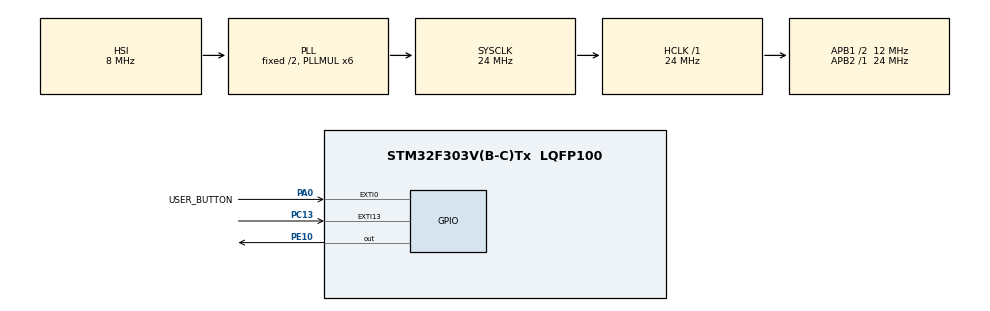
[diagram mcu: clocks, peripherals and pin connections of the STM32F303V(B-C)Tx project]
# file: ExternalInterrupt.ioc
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Mcu.Family=STM32F3
Mcu.Name=STM32F303V(B-C)Tx
Mcu.Package=LQFP100
NVIC.EXTI15_10_IRQn=true\:0\:1\:true\:false\:true\:true\:true\:true
NVIC.PriorityGroup=NVIC_PRIORITYGROUP_0
PA0.GPIO_Label=USER_BUTTON
PA0.Signal=GPXTI0
PC13.GPIO_ModeDefaultEXTI=GPIO_MODE_IT_FALLING
PC13.Signal=GPXTI13
PE10.Signal=GPIO_Output
ProjectManager.HeapSize=0x200
ProjectManager.StackSize=0x400
ProjectManager.TargetToolchain=STM32CubeIDE
RCC.AHBFreq_Value=24000000
RCC.APB1CLKDivider=RCC_HCLK_DIV2
RCC.APB1Freq_Value=12000000
RCC.APB1TimFreq_Value=24000000
RCC.APB2Freq_Value=24000000
RCC.APB2TimFreq_Value=24000000
RCC.CortexFreq_Value=24000000
RCC.HCLKFreq_Value=24000000
RCC.HSE_VALUE=8000000
RCC.HSI_VALUE=8000000
RCC.LSE_VALUE=32768
RCC.PLLMUL=RCC_PLL_MUL6
RCC.SYSCLKFreq_VALUE=24000000
RCC.SYSCLKSourceVirtual=RCC_SYSCLKSOURCE_PLLCLK
RCC.USBFreq_Value=24000000
board=STM32F3DISCOVERY

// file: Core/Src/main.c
/* USER CODE BEGIN Header */
/**
  ******************************************************************************
  * @file           : main.c
  * @brief          : Main program body
  ******************************************************************************
  * @attention
  *
  * Copyright (c) 2023 STMicroelectronics.
  * All rights reserved.
  *
  * This software is licensed under terms that can be found in the LICENSE file
  * in the root directory of this software component.
  * If no LICENSE file comes with this software, it is provided AS-IS.
  *
  ******************************************************************************
  */
/* USER CODE END Header */
#include "main.h"

void SystemClock_Config(void);
static void MX_GPIO_Init(void);
/* USER CODE BEGIN PFP */
uint8_t modeSelection =0;
/* USER CODE END PFP */

/* USER CODE BEGIN 0 */
void HAL_GPIO_EXTI_Callback(uint16_t GPIO_Pin)
{
  /* Prevent unused argument(s) compilation warning */
  UNUSED(GPIO_Pin);
  if(GPIO_Pin == USER_BUTTON_PIN_Pin){
	  modeSelection++;
	  if(modeSelection > 2){
		  modeSelection=0;
	  }
  }

}

/* USER CODE END 0 */

int main(void)
{

  /* MCU Configuration--------------------------------------------------------*/

  /* Reset of all peripherals, Initializes the Flash interface and the Systick. */
  HAL_Init();

  /* Configure the system clock */
  SystemClock_Config();

  /* Initialize all configured peripherals */
  MX_GPIO_Init();

  /* Infinite loop */
  while (1)
  {
	  if(modeSelection==0){
		  HAL_GPIO_TogglePin(GPIOE, GPIO_PIN_10);
		  HAL_Delay(200);
	  }
	  else if(modeSelection==1){
		  HAL_GPIO_WritePin(GPIOE, GPIO_PIN_10, GPIO_PIN_RESET);
		  HAL_Delay(200);
	  }
	  else if(modeSelection==2){
		  HAL_GPIO_WritePin(GPIOE, GPIO_PIN_10, GPIO_PIN_SET);
		  HAL_Delay(200);
	  }

  }
}

void SystemClock_Config(void)
{
  RCC_OscInitTypeDef RCC_OscInitStruct = {0};
  RCC_ClkInitTypeDef RCC_ClkInitStruct = {0};

  /** Initializes the RCC Oscillators according to the specified parameters
  * in the RCC_OscInitTypeDef structure.
  */
  RCC_OscInitStruct.OscillatorType = RCC_OSCILLATORTYPE_HSI;
  RCC_OscInitStruct.HSIState = RCC_HSI_ON;
  RCC_OscInitStruct.HSICalibrationValue = RCC_HSICALIBRATION_DEFAULT;
  RCC_OscInitStruct.PLL.PLLState = RCC_PLL_ON;
  RCC_OscInitStruct.PLL.PLLSource = RCC_PLLSOURCE_HSI;
  RCC_OscInitStruct.PLL.PLLMUL = RCC_PLL_MUL6;
  if (HAL_RCC_OscConfig(&RCC_OscInitStruct) != HAL_OK)
  {
    Error_Handler();
  }

  /** Initializes the CPU, AHB and APB buses clocks
  */
  RCC_ClkInitStruct.ClockType = RCC_CLOCKTYPE_HCLK|RCC_CLOCKTYPE_SYSCLK
                              |RCC_CLOCKTYPE_PCLK1|RCC_CLOCKTYPE_PCLK2;
  RCC_ClkInitStruct.SYSCLKSource = RCC_SYSCLKSOURCE_PLLCLK;
  RCC_ClkInitStruct.AHBCLKDivider = RCC_SYSCLK_DIV1;
  RCC_ClkInitStruct.APB1CLKDivider = RCC_HCLK_DIV2;
  RCC_ClkInitStruct.APB2CLKDivider = RCC_HCLK_DIV1;

  if (HAL_RCC_ClockConfig(&RCC_ClkInitStruct, FLASH_LATENCY_0) != HAL_OK)
  {
    Error_Handler();
  }
}

static void MX_GPIO_Init(void)
{
  GPIO_InitTypeDef GPIO_InitStruct = {0};

  /* GPIO Ports Clock Enable */
  __HAL_RCC_GPIOC_CLK_ENABLE();
  __HAL_RCC_GPIOA_CLK_ENABLE();
  __HAL_RCC_GPIOE_CLK_ENABLE();

  /*Configure GPIO pin Output Level */
  HAL_GPIO_WritePin(GPIOE, GPIO_PIN_10, GPIO_PIN_RESET);

  /*Configure GPIO pin : PC13 */
  GPIO_InitStruct.Pin = GPIO_PIN_13;
  GPIO_InitStruct.Mode = GPIO_MODE_IT_FALLING;
  GPIO_InitStruct.Pull = GPIO_NOPULL;
  HAL_GPIO_Init(GPIOC, &GPIO_InitStruct);

  /*Configure GPIO pin : USER_BUTTON_PIN_Pin */
  GPIO_InitStruct.Pin = USER_BUTTON_PIN_Pin;
  GPIO_InitStruct.Mode = GPIO_MODE_IT_RISING;
  GPIO_InitStruct.Pull = GPIO_NOPULL;
  HAL_GPIO_Init(USER_BUTTON_PIN_GPIO_Port, &GPIO_InitStruct);

  /*Configure GPIO pin : PE10 */
  GPIO_InitStruct.Pin = GPIO_PIN_10;
  GPIO_InitStruct.Mode = GPIO_MODE_OUTPUT_PP;
  GPIO_InitStruct.Pull = GPIO_NOPULL;
  GPIO_InitStruct.Speed = GPIO_SPEED_FREQ_LOW;
  HAL_GPIO_Init(GPIOE, &GPIO_InitStruct);

  /* EXTI interrupt init*/
  HAL_NVIC_SetPriority(EXTI15_10_IRQn, 0, 1);
  HAL_NVIC_EnableIRQ(EXTI15_10_IRQn);

}

void Error_Handler(void)
{
  __disable_irq();
  while (1)
  {
  }
}
